# MCXN947_cm33_core0 register map
Vendor: nxp.com; File version: 1.0
CPU: CM33 r2p0, little endian, MPU, FPU, VTOR, 3 interrupt priority bits
Registers are 32-bit, read-write, reset 0x0 unless marked. A register's access mark holds for its fields unless they carry their own. Offsets are from the block's base; [hi:lo] are bit positions.

## ENC0 — ENC
Base 0x400CF000
Same registers: ENC1 0x400D1000
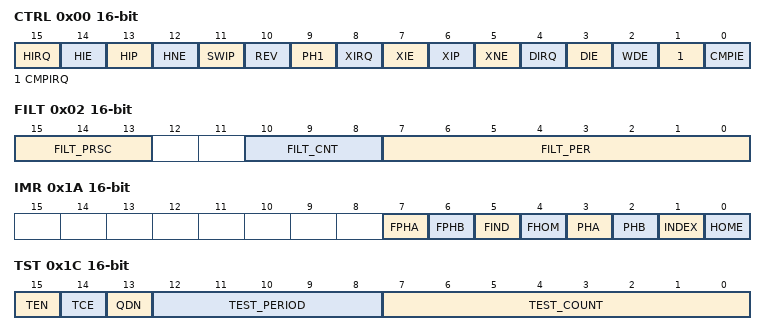
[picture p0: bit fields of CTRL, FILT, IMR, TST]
0x00 CTRL 16-bit — Control
  [15] HIRQ write-1-clears — HOME Signal Transition Interrupt Request
    0=NOTRANS (Not occurred); 1=TRANSI (Occurred)
  [14] HIE — HOME Interrupt Enable
    0=DISABLED; 1=ENABLED
  [13] HIP — Enable HOME to Initialize Position Counters UPOS and LPOS
    0=NOACTION; 1=HOME (HOME signal initializes the position counter)
  [12] HNE — Use Negative Edge of HOME Input
    0=POS (Use positive-going edge-to-trigger initialization of position counters UPOS and LPOS); 1=NEG (Use negative-going edge-to-trigger initialization of position counters UPOS and LPOS)
  [11] SWIP — Software-Triggered Initialization of Position Counters UPOS and LPOS
    0=NOACTION; 1=INIT (Initialize position counter)
  [10] REV — Enable Reverse Direction Counting
    0=NORMAL (Counts normally); 1=REVERSE (Counts in the reverse direction)
  [9] PH1 — Enable Signal Phase Count Mode
    0=USE (Uses the standard quadrature decoder, where PHASEA and PHASEB represent a two-phase quadrature signal.); 1=BYPASS (Bypasses the quadrature decoder. A positive transition of the PHASEA input generates a count signal. PHASEB input and CTRL[REV] controls the counter direction. If the value of CTRL[REV] and PHASEB are identical; then count is up. If the value of CTRL[REV] and PHASEB is different, then count is down.)
  [8] XIRQ write-1-clears — INDEX Pulse Interrupt Request
    0=NOIND (Not occurred); 1=INDEX (Occurred)
  [7] XIE — INDEX Pulse Interrupt Enable
    0=DISABLED; 1=ENABLED
  [6] XIP — INDEX Triggered Initialization of Position Counters UPOS and LPOS
    0=NOINT (Does not initialize); 1=INT (Initializes)
  [5] XNE — Select Positive and Negative Edge of INDEX and PRESET Pulse
    0=Use positive edge; 1=Use negative edge
  [4] DIRQ write-1-clears — Watchdog Timeout Interrupt Request
    0=NOINT (Not occurred); 1=INT (Occurred)
  [3] DIE — Watchdog Timeout Interrupt Enable
    0=DISABLED; 1=ENABLED
  [2] WDE — Watchdog Enable
    0=DISABLED; 1=ENABLED
  [1] CMPIRQ write-1-clears — Compare Interrupt Request
    0=NOMAT (No match has occurred); 1=MAT (COMP match has occurred)
  [0] CMPIE — Compare Interrupt Enable
    0=DISABLED; 1=ENABLED
0x02 FILT 16-bit — Input Filter
  [15:13] FILT_PRSC — Prescaler Divide IPBus Clock to FILT Clock
  [10:8] FILT_CNT — Input Filter Sample Count
  [7:0] FILT_PER — Input Filter Sample Period
0x04 WTR 16-bit — Watchdog Timeout
  [15:0] WDOG
0x06 POSD 16-bit — Position Difference Counter
0x08 POSDH 16-bit ro — Position Difference Hold
0x0A REV 16-bit — Revolution Counter
0x0C REVH 16-bit ro — Revolution Hold
0x0E UPOS 16-bit — Upper Position Counter
  [15:0] POS
0x10 LPOS 16-bit — Lower Position Counter
  [15:0] POS
0x12 UPOSH 16-bit ro — Upper Position Hold
  [15:0] POSH
0x14 LPOSH 16-bit ro — Lower Position Hold
  [15:0] POSH
0x16 UINIT 16-bit — Upper Initialization
  [15:0] INIT
0x18 LINIT 16-bit — Lower Initialization
  [15:0] INIT
0x1A IMR 16-bit ro — Input Monitor
  [7] FPHA, [6] FPHB, [5] FIND, [4] FHOM, [3] PHA, [2] PHB, [1] INDEX, [0] HOME
0x1C TST 16-bit — Test
  [15] TEN — Test Mode Enable
    0=DISABLED; 1=ENABLED
  [14] TCE — Test Counter Enable
    0=DISABLED; 1=ENABLED
  [13] QDN — Quadrature Decoder Negative Signal
    0=POSITIVE (Positive quadrature decoder signal); 1=NEGATIVE (Negative quadrature decoder signal)
  [12:8] TEST_PERIOD
  [7:0] TEST_COUNT
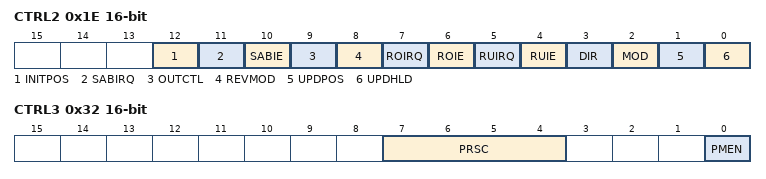
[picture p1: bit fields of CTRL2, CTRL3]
0x1E CTRL2 16-bit — Control 2
  [12] INITPOS — Initialize Position Registers
    0=NOINIT (Don't initialize position counter); 1=INIT (Initialize position counter)
  [11] SABIRQ write-1-clears — Simultaneous PHASEA and PHASEB Change Interrupt Request
    0=NOSIMUL (No simultaneous change has occurred); 1=SIMUL (A simultaneous change has occurred)
  [10] SABIE — Simultaneous PHASEA and PHASEB Change Interrupt Enable
    0=DISABLED; 1=ENABLED
  [9] OUTCTL — Output Control
    0=COMPARE (POSMATCH pulses when a match occurs between the position counters (POS) and the corresponding compare value (COMP )); 1=READ (POSMATCH pulses when the UPOS, LPOS, REV, or POSD registers are read)
  [8] REVMOD — Revolution Counter Modulus Enable
    0=INDEX (Use INDEX pulse); 1=COUNT (Use modulus counting roll-over or roll-under)
  [7] ROIRQ write-1-clears — Roll-over Interrupt Request
    0=NOROLL (Did not occur); 1=ROLL (Occurred)
  [6] ROIE — Roll-over Interrupt Enable
    0=DISABLED; 1=ENABLED
  [5] RUIRQ write-1-clears — Roll-under Interrupt Request
    0=NOROLL (No roll-under has occurred); 1=ROLL (Roll-under has occurred)
  [4] RUIE — Roll-under Interrupt Enable
    0=DISABLED; 1=ENABLED
  [3] DIR ro — Count Direction Flag
    0=DOWN (Down direction); 1=UP (Up direction)
  [2] MOD — Enable Modulo Counting
    0=DISABLED; 1=ENABLED
  [1] UPDPOS — Update Position Registers
    0=NOACTION; 1=CLEAR
  [0] UPDHLD — Update Hold Registers
    0=DISABLED; 1=ENABLED
0x20 UMOD 16-bit — Upper Modulus
  [15:0] MOD
0x22 LMOD 16-bit — Lower Modulus
  [15:0] MOD
0x24 UCOMP 16-bit reset 0xFFFF — Upper Position Compare
  [15:0] COMP
0x26 LCOMP 16-bit reset 0xFFFF — Lower Position Compare
  [15:0] COMP
0x28 LASTEDGE 16-bit ro reset 0xFFFF — Last Edge Time
  [15:0] LASTEDGE — Last Edge Time Counter
0x2A LASTEDGEH 16-bit ro reset 0xFFFF — Last Edge Time Hold
0x2C POSDPER 16-bit ro reset 0xFFFF — Position Difference Period Counter
  [15:0] POSDPER — Position difference period
0x2E POSDPERBFR 16-bit ro reset 0xFFFF — Position Difference Period Buffer
  [15:0] POSDPERBFR — Position difference period buffer
0x30 POSDPERH 16-bit ro reset 0xFFFF — Position Difference Period Hold
  [15:0] POSDPERH — Position difference period hold
0x32 CTRL3 16-bit — Control 3
  [7:4] PRSC — Prescaler
  [0] PMEN — Period Measurement Function Enable
    0=NOTUSED; 1=USED
